VERSION ""

NS_ :

BS_:

BU_: SungrowSH50RS BYDHVM

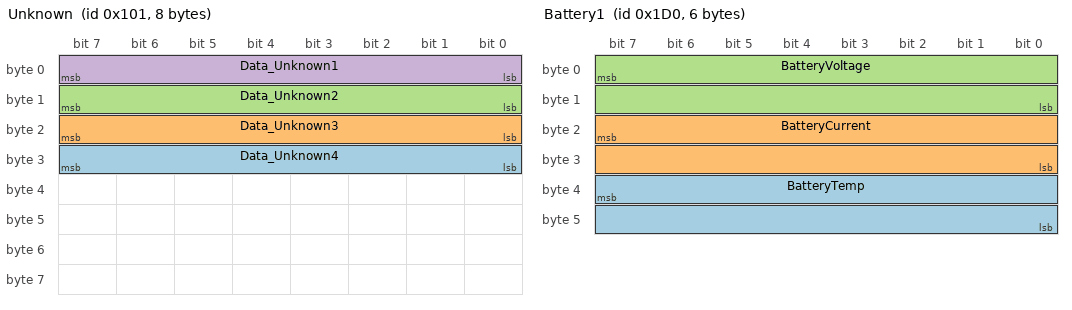
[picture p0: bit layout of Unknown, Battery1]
BO_ 257 Unknown: 8 Vector__XXX
 SG_ Data_Unknown4 : 31|8@0+ (1,0) [0|255] "" Vector__XXX
 SG_ Data_Unknown3 : 23|8@0+ (1,0) [0|255] "" Vector__XXX
 SG_ Data_Unknown2 : 15|8@0+ (1,0) [0|255] "" Vector__XXX
 SG_ Data_Unknown1 : 7|8@0+ (1,0) [0|255] "" Vector__XXX

BO_ 528 Battery3: 4 BYDHVM
 SG_ BatteryMinCellTemp : 23|16@0+ (0.1,0) [0|6553.5] "*C" Vector__XXX
 SG_ BatteryMaxCellTemp : 7|16@0+ (0.1,0) [0|6553.5] "*C" Vector__XXX

BO_ 464 Battery1: 6 BYDHVM
 SG_ BatteryTemp : 39|16@0- (0.1,0) [-3276.8|3276.7] "*C" Vector__XXX
 SG_ BatteryCurrent : 23|16@0- (0.1,0) [-3276.8|3276.7] "A" Vector__XXX
 SG_ BatteryVoltage : 7|16@0- (0.1,0) [-3276.8|3276.7] "V" Vector__XXX

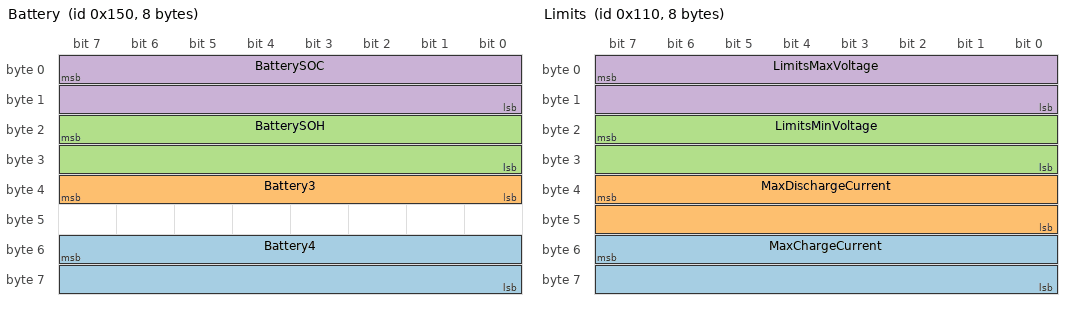
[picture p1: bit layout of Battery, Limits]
BO_ 336 Battery: 8 Vector__XXX
 SG_ Battery4 : 55|16@0- (1,0) [-32768|32767] "Unkn" Vector__XXX
 SG_ Battery3 : 39|8@0- (1,0) [-32768|32767] "" Vector__XXX
 SG_ BatterySOH : 23|16@0+ (0.01,0) [0|655.35] "%" Vector__XXX
 SG_ BatterySOC : 7|16@0+ (0.01,0) [0|655.35] "%" Vector__XXX

BO_ 273 TimeStamp: 4 Vector__XXX
 SG_ TimeStamp : 7|32@0+ (1,0) [-2147483648|2147483647] "T" Vector__XXX

BO_ 272 Limits: 8 BYDHVM
 SG_ MaxChargeCurrent : 55|16@0- (0.1,0) [-3276.8|3276.7] "A" Vector__XXX
 SG_ MaxDischargeCurrent : 39|16@0- (0.1,0) [-3276.8|3276.7] "A" Vector__XXX
 SG_ LimitsMinVoltage : 23|16@0+ (0.1,0) [0|6553.5] "V" Vector__XXX
 SG_ LimitsMaxVoltage : 7|16@0+ (0.1,0) [0|6553.5] "V" Vector__XXX

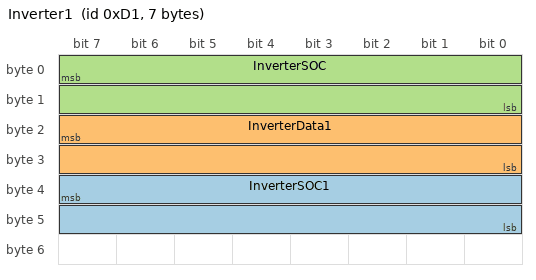
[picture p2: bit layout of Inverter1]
BO_ 209 Inverter1: 7 Vector__XXX
 SG_ InverterSOC1 : 39|16@0- (0.1,0) [-3276.8|3276.7] "%" Vector__XXX
 SG_ InverterData1 : 23|16@0- (1,0) [-32768|32767] "" Vector__XXX
 SG_ InverterSOC : 7|16@0+ (0.1,0) [0|100] "%" Vector__XXX

BO_ 145 Inverter: 7 Vector__XXX
 SG_ Inverter1 : 55|16@0- (1,0) [-32768|32767] "Unkn" Vector__XXX
 SG_ Inverter : 39|16@0- (1,0) [-32768|32767] "Unkn" Vector__XXX
 SG_ InverterBatteryCurrent : 23|16@0- (0.1,0) [-3276.8|3276.7] "A" Vector__XXX
 SG_ InverterBatteryVoltage : 7|16@0+ (0.1,0) [0|6553.5] "V" Vector__XXX

CM_ BO_ 528 "Message sent every 10 seconds";
CM_ BO_ 464 "Message sent every 10 seconds";
CM_ BO_ 272 "Message sent every 2 seconds";
BA_DEF_  "BusType" STRING ;
BA_DEF_DEF_  "BusType" "CAN";
